# MSP430F249 register map
Vendor: msp430gen; File version: v0.4.0
Registers are 8-bit, read-write, reset 0x0 unless marked. A register's access mark holds for its fields unless they carry their own. Offsets are from the block's base; [hi:lo] are bit positions; {n}, {i} and the like mark numbered series.

## USCI_A0_SPI_MODE
Base 0x00000060
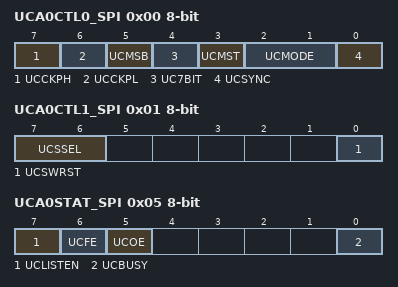
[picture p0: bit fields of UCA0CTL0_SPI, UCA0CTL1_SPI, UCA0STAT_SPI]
0x00 UCA0CTL0_SPI — USCI A0 Control Register 0
  [7] UCCKPH — Sync. Mode: Clock Phase
  [6] UCCKPL — Sync. Mode: Clock Polarity
  [5] UCMSB — Sync. Mode: MSB first 0:LSB / 1:MSB
  [4] UC7BIT — Sync. Mode: Data Bits 0:8-bits / 1:7-bits
  [3] UCMST — Sync. Mode: Master Select
  [2:1] UCMODE — Sync. Mode: USCI Mode 1
    {v}=Sync. Mode: USCI Mode: {v} (v=0..3)
  [0] UCSYNC — Sync-Mode 0:UART-Mode / 1:SPI-Mode
0x01 UCA0CTL1_SPI — USCI A0 Control Register 1
  [7:6] UCSSEL — USCI 1 Clock Source Select 1
    {v}=USCI 0 Clock Source: {v} (v=0..3)
  [0] UCSWRST — USCI Software Reset
0x02 UCA0BR0_SPI — USCI A0 Baud Rate 0
0x03 UCA0BR1_SPI — USCI A0 Baud Rate 1
0x04 UCA0MCTL_SPI — USCI A0 Modulation Control
0x05 UCA0STAT_SPI — USCI A0 Status Register
  [7] UCLISTEN — USCI Listen mode
  [6] UCFE — USCI Frame Error Flag
  [5] UCOE — USCI Overrun Error Flag
  [0] UCBUSY — USCI Busy Flag
0x06 UCA0RXBUF_SPI — USCI A0 Receive Buffer
0x07 UCA0TXBUF_SPI — USCI A0 Transmit Buffer

## USCI_B0_I2C_MODE
Base 0x00000068
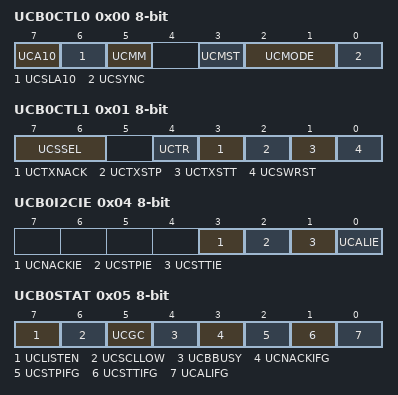
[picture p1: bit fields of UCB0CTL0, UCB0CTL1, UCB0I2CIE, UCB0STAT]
0x00 UCB0CTL0 — USCI B0 Control Register 0
  [7] UCA10 — 10-bit Address Mode
  [6] UCSLA10 — 10-bit Slave Address Mode
  [5] UCMM — Multi-Master Environment
  [3] UCMST — Sync. Mode: Master Select
  [2:1] UCMODE — Sync. Mode: USCI Mode 1
    {v}=Sync. Mode: USCI Mode: {v} (v=0..3)
  [0] UCSYNC — Sync-Mode 0:UART-Mode / 1:SPI-Mode
0x01 UCB0CTL1 — USCI B0 Control Register 1
  [7:6] UCSSEL — USCI 1 Clock Source Select 1
    {v}=USCI 0 Clock Source: {v} (v=0..3)
  [4] UCTR — Transmit/Receive Select/Flag
  [3] UCTXNACK — Transmit NACK
  [2] UCTXSTP — Transmit STOP
  [1] UCTXSTT — Transmit START
  [0] UCSWRST — USCI Software Reset
0x02 UCB0BR0 — USCI B0 Baud Rate 0
0x03 UCB0BR1 — USCI B0 Baud Rate 1
0x04 UCB0I2CIE — USCI B0 I2C Interrupt Enable Register
  [3] UCNACKIE — NACK Condition interrupt enable
  [2] UCSTPIE — STOP Condition interrupt enable
  [1] UCSTTIE — START Condition interrupt enable
  [0] UCALIE — Arbitration Lost interrupt enable
0x05 UCB0STAT — USCI B0 Status Register
  [7] UCLISTEN — USCI Listen mode
  [6] UCSCLLOW — SCL low
  [5] UCGC — General Call address received Flag
  [4] UCBBUSY — Bus Busy Flag
  [3] UCNACKIFG — NAK Condition interrupt Flag
  [2] UCSTPIFG — STOP Condition interrupt Flag
  [1] UCSTTIFG — START Condition interrupt Flag
  [0] UCALIFG — Arbitration Lost interrupt Flag
0x06 UCB0RXBUF — USCI B0 Receive Buffer
0x07 UCB0TXBUF — USCI B0 Transmit Buffer
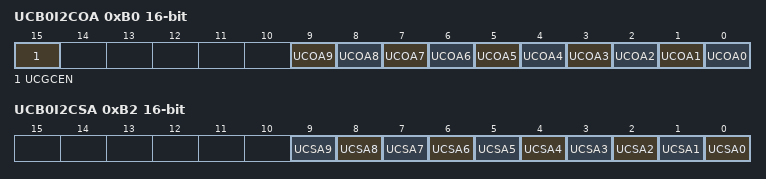
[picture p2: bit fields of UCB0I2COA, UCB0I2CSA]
0xB0 UCB0I2COA 16-bit — USCI B0 I2C Own Address
  [15] UCGCEN — I2C General Call enable
  [n] UCOA{n} (n=0..9) — I2C Own Address {n}
0xB2 UCB0I2CSA 16-bit — USCI B0 I2C Slave Address
  [n] UCSA{n} (n=0..9) — I2C Slave Address {n}

## USCI_B0_SPI_MODE
Base 0x00000068
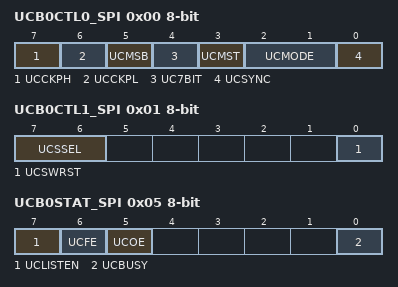
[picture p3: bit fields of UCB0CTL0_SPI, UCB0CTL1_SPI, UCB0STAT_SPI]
0x00 UCB0CTL0_SPI — USCI B0 Control Register 0
  [7] UCCKPH — Sync. Mode: Clock Phase
  [6] UCCKPL — Sync. Mode: Clock Polarity
  [5] UCMSB — Sync. Mode: MSB first 0:LSB / 1:MSB
  [4] UC7BIT — Sync. Mode: Data Bits 0:8-bits / 1:7-bits
  [3] UCMST — Sync. Mode: Master Select
  [2:1] UCMODE — Sync. Mode: USCI Mode 1
    {v}=Sync. Mode: USCI Mode: {v} (v=0..3)
  [0] UCSYNC — Sync-Mode 0:UART-Mode / 1:SPI-Mode
0x01 UCB0CTL1_SPI — USCI B0 Control Register 1
  [7:6] UCSSEL — USCI 1 Clock Source Select 1
    {v}=USCI 0 Clock Source: {v} (v=0..3)
  [0] UCSWRST — USCI Software Reset
0x02 UCB0BR0_SPI — USCI B0 Baud Rate 0
0x03 UCB0BR1_SPI — USCI B0 Baud Rate 1
0x05 UCB0STAT_SPI — USCI B0 Status Register
  [7] UCLISTEN — USCI Listen mode
  [6] UCFE — USCI Frame Error Flag
  [5] UCOE — USCI Overrun Error Flag
  [0] UCBUSY — USCI Busy Flag
0x06 UCB0RXBUF_SPI — USCI B0 Receive Buffer
0x07 UCB0TXBUF_SPI — USCI B0 Transmit Buffer

## ADC12
Base 0x00000080
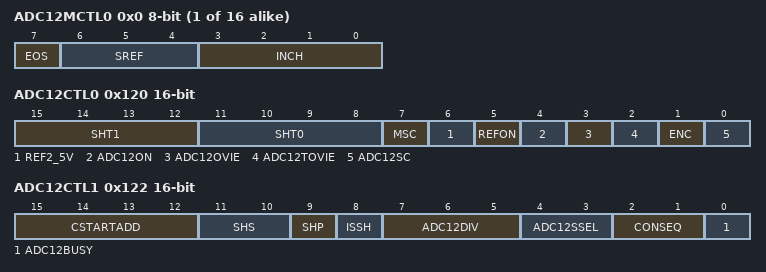
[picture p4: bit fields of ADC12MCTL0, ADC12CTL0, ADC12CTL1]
{0x0+i} ADC12MCTL{i} (i=0..15) — ADC12 Memory Control {i}
  [7] EOS — ADC12 End of Sequence
  [6:4] SREF — ADC12 Select Reference Bit 0
    {v}=ADC12 Select Reference {v} (v=0..7)
  [3:0] INCH — ADC12 Input Channel Select Bit 0
    {v}=ADC12 Input Channel {v} (v=0..15)
{0xC0+2i} ADC12MEM{i} 16-bit (i=0..15) — ADC12 Conversion Memory {i}
0x120 ADC12CTL0 16-bit — ADC12 Control 0
  [15:12] SHT1 — ADC12 Sample Hold 0 Select 0
    {v}=ADC12 Sample Hold 1 Select Bit: {v} (v=0..15)
  [11:8] SHT0 — ADC12 Sample Hold 0 Select 0
    {v}=ADC12 Sample Hold 0 Select Bit: {v} (v=0..15)
  [7] MSC — ADC12 Multiple SampleConversion
  [6] REF2_5V — ADC12 Ref 0:1.5V / 1:2.5V
  [5] REFON — ADC12 Reference on
  [4] ADC12ON — ADC12 On/enable
  [3] ADC12OVIE — ADC12 Overflow interrupt enable
  [2] ADC12TOVIE — ADC12 Timer Overflow interrupt enable
  [1] ENC — ADC12 Enable Conversion
  [0] ADC12SC — ADC12 Start Conversion
0x122 ADC12CTL1 16-bit — ADC12 Control 1
  [15:12] CSTARTADD — ADC12 Conversion Start Address 0
    {v}=ADC12 Conversion Start Address: {v} (v=0..15)
  [11:10] SHS — ADC12 Sample/Hold Source 0
    {v}=ADC12 Sample/Hold Source: {v} (v=0..3)
  [9] SHP — ADC12 Sample/Hold Pulse Mode
  [8] ISSH — ADC12 Invert Sample Hold Signal
  [7:5] ADC12DIV — ADC12 Clock Divider Select 0
    {v}=ADC12 Clock Divider Select: {v} (v=0..7)
  [4:3] ADC12SSEL — ADC12 Clock Source Select 0
    {v}=ADC12 Clock Source Select: {v} (v=0..3)
  [2:1] CONSEQ — ADC12 Conversion Sequence Select 0
    {v}=ADC12 Conversion Sequence Select: {v} (v=0..3)
  [0] ADC12BUSY
0x124 ADC12IFG 16-bit — ADC12 Interrupt Flag
0x126 ADC12IE 16-bit — ADC12 Interrupt Enable
0x128 ADC12IV 16-bit — ADC12 Interrupt Vector Word
